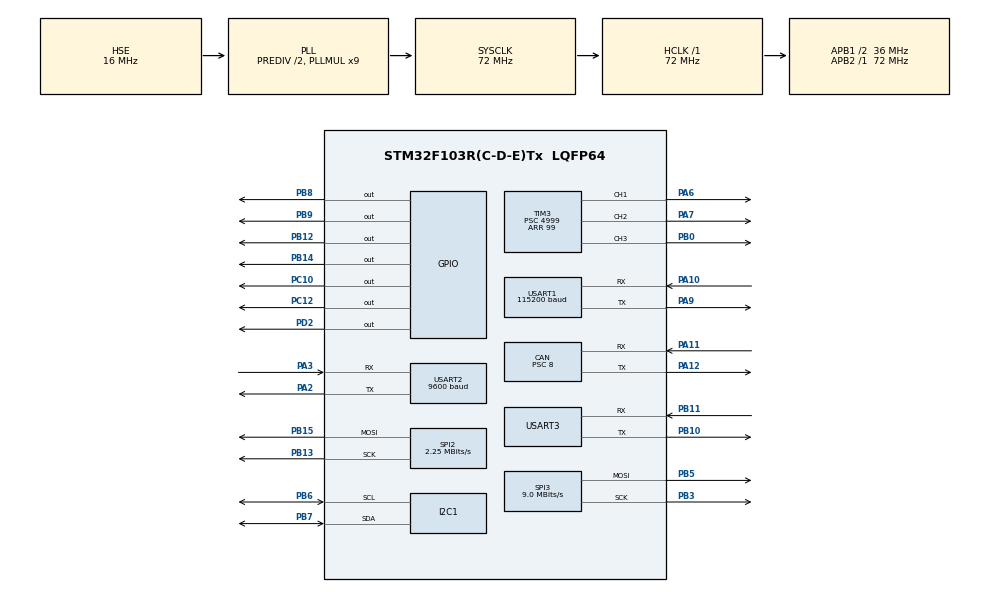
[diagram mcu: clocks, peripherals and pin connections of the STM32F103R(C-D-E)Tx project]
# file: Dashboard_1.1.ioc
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CAN.BS1=CAN_BS1_12TQ
CAN.BS2=CAN_BS2_5TQ
CAN.CalculateTimeBit=4000
CAN.CalculateTimeQuantum=222.22222222222223
CAN.Prescaler=8
I2C1.DutyCycle=I2C_DUTYCYCLE_2
I2C1.I2C_Mode=I2C_Fast
Mcu.Family=STM32F1
Mcu.Name=STM32F103R(C-D-E)Tx
Mcu.Package=LQFP64
NVIC.CAN1_RX1_IRQn=true\:0\:0\:false\:false\:true\:true\:true
NVIC.CAN1_SCE_IRQn=true\:0\:0\:false\:false\:true\:true\:true
NVIC.PriorityGroup=NVIC_PRIORITYGROUP_4
NVIC.USB_HP_CAN1_TX_IRQn=true\:0\:0\:false\:false\:true\:true\:true
NVIC.USB_LP_CAN1_RX0_IRQn=true\:0\:0\:false\:false\:true\:true\:true
PA10.Mode=Asynchronous
PA10.Signal=USART1_RX
PA11.GPIO_PuPd=GPIO_PULLUP
PA11.Mode=Master
PA11.Signal=CAN_RX
PA12.Mode=Master
PA12.Signal=CAN_TX
PA13.Mode=Serial_Wire
PA13.Signal=SYS_JTMS-SWDIO
PA14.Mode=Serial_Wire
PA14.Signal=SYS_JTCK-SWCLK
PA2.Mode=Asynchronous
PA2.Signal=USART2_TX
PA3.Mode=Asynchronous
PA3.Signal=USART2_RX
PA6.Signal=S_TIM3_CH1
PA7.Signal=S_TIM3_CH2
PA9.Mode=Asynchronous
PA9.Signal=USART1_TX
PB0.Signal=S_TIM3_CH3
PB10.Mode=Asynchronous
PB10.Signal=USART3_TX
PB11.Mode=Asynchronous
PB11.Signal=USART3_RX
PB12.GPIO_ModeDefaultOutputPP=GPIO_MODE_OUTPUT_PP
PB12.GPIO_PuPd=GPIO_NOPULL
PB12.GPIO_Speed=GPIO_SPEED_FREQ_LOW
PB12.PinState=GPIO_PIN_RESET
PB12.Signal=GPIO_Output
PB13.Mode=TX_Only_Simplex_Unidirect_Master
PB13.Signal=SPI2_SCK
PB14.GPIO_ModeDefaultOutputPP=GPIO_MODE_OUTPUT_PP
PB14.GPIO_PuPd=GPIO_NOPULL
PB14.GPIO_Speed=GPIO_SPEED_FREQ_LOW
PB14.PinState=GPIO_PIN_RESET
PB14.Signal=GPIO_Output
PB15.Mode=TX_Only_Simplex_Unidirect_Master
PB15.Signal=SPI2_MOSI
PB3.Mode=TX_Only_Simplex_Unidirect_Master
PB3.Signal=SPI3_SCK
PB5.Mode=TX_Only_Simplex_Unidirect_Master
PB5.Signal=SPI3_MOSI
PB6.Mode=I2C
PB6.Signal=I2C1_SCL
PB7.Mode=I2C
PB7.Signal=I2C1_SDA
PB8.GPIO_ModeDefaultOutputPP=GPIO_MODE_OUTPUT_PP
PB8.GPIO_PuPd=GPIO_NOPULL
PB8.GPIO_Speed=GPIO_SPEED_FREQ_LOW
PB8.PinState=GPIO_PIN_RESET
PB8.Signal=GPIO_Output
PB9.GPIO_ModeDefaultOutputPP=GPIO_MODE_OUTPUT_PP
PB9.GPIO_PuPd=GPIO_NOPULL
PB9.GPIO_Speed=GPIO_SPEED_FREQ_LOW
PB9.PinState=GPIO_PIN_RESET
PB9.Signal=GPIO_Output
PC10.GPIO_ModeDefaultOutputPP=GPIO_MODE_OUTPUT_PP
PC10.GPIO_PuPd=GPIO_NOPULL
PC10.GPIO_Speed=GPIO_SPEED_FREQ_LOW
PC10.PinState=GPIO_PIN_RESET
PC10.Signal=GPIO_Output
PC12.GPIO_ModeDefaultOutputPP=GPIO_MODE_OUTPUT_PP
PC12.GPIO_PuPd=GPIO_NOPULL
PC12.GPIO_Speed=GPIO_SPEED_FREQ_LOW
PC12.PinState=GPIO_PIN_RESET
PC12.Signal=GPIO_Output
PC14-OSC32_IN.Mode=LSE-External-Oscillator
PC14-OSC32_IN.Signal=RCC_OSC32_IN
PC15-OSC32_OUT.Mode=LSE-External-Oscillator
PC15-OSC32_OUT.Signal=RCC_OSC32_OUT
PD0-OSC_IN.Mode=HSE-External-Oscillator
PD0-OSC_IN.Signal=RCC_OSC_IN
PD1-OSC_OUT.Mode=HSE-External-Oscillator
PD1-OSC_OUT.Signal=RCC_OSC_OUT
PD2.GPIO_ModeDefaultOutputPP=GPIO_MODE_OUTPUT_PP
PD2.GPIO_PuPd=GPIO_NOPULL
PD2.GPIO_Speed=GPIO_SPEED_FREQ_LOW
PD2.PinState=GPIO_PIN_RESET
PD2.Signal=GPIO_Output
ProjectManager.HeapSize=0x200
ProjectManager.StackSize=0x400
ProjectManager.TargetToolchain=STM32CubeIDE
RCC.AHBFreq_Value=72000000
RCC.APB1CLKDivider=RCC_HCLK_DIV2
RCC.APB1Freq_Value=36000000
RCC.APB1TimFreq_Value=72000000
RCC.APB2Freq_Value=72000000
RCC.APB2TimFreq_Value=72000000
RCC.HCLKFreq_Value=72000000
RCC.HSEDivPLL=RCC_HSE_PREDIV_DIV2
RCC.HSE_VALUE=16000000
RCC.PLLMUL=RCC_PLL_MUL9
RCC.PLLSourceVirtual=RCC_PLLSOURCE_HSE
RCC.SYSCLKFreq_VALUE=72000000
RCC.SYSCLKSource=RCC_SYSCLKSOURCE_PLLCLK
RCC.USBFreq_Value=72000000
SH.S_TIM3_CH1.0=TIM3_CH1,PWM Generation1 CH1
SH.S_TIM3_CH2.0=TIM3_CH2,PWM Generation2 CH2
SH.S_TIM3_CH3.0=TIM3_CH3,PWM Generation3 CH3
SPI2.BaudRatePrescaler=SPI_BAUDRATEPRESCALER_16
SPI2.CalculateBaudRate=2.25 MBits/s
SPI2.Direction=SPI_DIRECTION_2LINES
SPI2.FirstBit=SPI_FIRSTBIT_LSB
SPI2.Mode=SPI_MODE_MASTER
SPI2.VirtualType=VM_MASTER
SPI3.BaudRatePrescaler=SPI_BAUDRATEPRESCALER_4
SPI3.CalculateBaudRate=9.0 MBits/s
SPI3.Direction=SPI_DIRECTION_2LINES
SPI3.Mode=SPI_MODE_MASTER
SPI3.VirtualType=VM_MASTER
TIM3.Channel-PWM\ Generation1\ CH1=TIM_CHANNEL_1
TIM3.Channel-PWM\ Generation2\ CH2=TIM_CHANNEL_2
TIM3.Channel-PWM\ Generation3\ CH3=TIM_CHANNEL_3
TIM3.Period=99
TIM3.Prescaler=4999
USART1.BaudRate=115200
USART1.VirtualMode=VM_ASYNC
USART2.BaudRate=9600
USART2.VirtualMode=VM_ASYNC
USART3.VirtualMode=VM_ASYNC
VP_TIM3_VS_ClockSourceINT.Mode=Internal
board=custom

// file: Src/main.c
/* USER CODE BEGIN Header */
/**
  ******************************************************************************
  * @file           : main.c
  * @brief          : Main program body
  ******************************************************************************
  * @attention
  *
  * <h2><center>&copy; Copyright (c) 2019 STMicroelectronics.
  * All rights reserved.</center></h2>
  *
  * This software component is licensed by ST under BSD 3-Clause license,
  * the "License"; You may not use this file except in compliance with the
  * License. You may obtain a copy of the License at:
  *                        opensource.org/licenses/BSD-3-Clause
  *
  ******************************************************************************
  */
/* USER CODE END Header */

#include "main.h"
#include "can.h"
#include "i2c.h"
#include "spi.h"
#include "tim.h"
#include "usart.h"
#include "gpio.h"

/* USER CODE BEGIN Includes */

#include "../GUI/gui.h"
#include "../GUI/gui.c"

#define SOFTWARE_VERSION "1.0"
#define SOFTWARE_RELASE_DATE "18.03.2019"

/* USER CODE END Includes */

/* USER CODE BEGIN PV */
/* Private variables ---------------------------------------------------------*/

/* USER CODE END PV */

void SystemClock_Config(void);
/* USER CODE BEGIN PFP */
/* Private function prototypes -----------------------------------------------*/

/* USER CODE END PFP */

int main(void)
{
  /* USER CODE BEGIN 1 */

// HAL_DBGMCU_EnableDBGSleepMode();
// HAL_DBGMCU_DisableDBGStopMode();
// HAL_DBGMCU_EnableDBGStandbyMode();

  /* USER CODE END 1 */

  /* MCU Configuration--------------------------------------------------------*/

  /* Reset of all peripherals, Initializes the Flash interface and the Systick. */
  HAL_Init();

  /* Configure the system clock */
  SystemClock_Config();

  /* Initialize all configured peripherals */
  MX_GPIO_Init();
  MX_CAN_Init();
  MX_I2C1_Init();
  MX_SPI2_Init();
  MX_SPI3_Init();
  MX_TIM3_Init();
  MX_USART1_UART_Init();
  MX_USART2_UART_Init();
  MX_USART3_UART_Init();
  /* USER CODE BEGIN 2 */

	gui_init();
	gui_screen_intro(); //test

//	gui_test();

  /* USER CODE END 2 */

  /* Infinite loop */
  while (1)
  {

    /* USER CODE BEGIN 3 */

	  gui_screen_main();

  }
  /* USER CODE END 3 */
}

void SystemClock_Config(void)
{
  RCC_OscInitTypeDef RCC_OscInitStruct = {0};
  RCC_ClkInitTypeDef RCC_ClkInitStruct = {0};

  /** Initializes the CPU, AHB and APB busses clocks
  */
  RCC_OscInitStruct.OscillatorType = RCC_OSCILLATORTYPE_HSE;
  RCC_OscInitStruct.HSEState = RCC_HSE_ON;
  RCC_OscInitStruct.HSEPredivValue = RCC_HSE_PREDIV_DIV2;
  RCC_OscInitStruct.HSIState = RCC_HSI_ON;
  RCC_OscInitStruct.PLL.PLLState = RCC_PLL_ON;
  RCC_OscInitStruct.PLL.PLLSource = RCC_PLLSOURCE_HSE;
  RCC_OscInitStruct.PLL.PLLMUL = RCC_PLL_MUL9;
  if (HAL_RCC_OscConfig(&RCC_OscInitStruct) != HAL_OK)
  {
    Error_Handler();
  }
  /** Initializes the CPU, AHB and APB busses clocks
  */
  RCC_ClkInitStruct.ClockType = RCC_CLOCKTYPE_HCLK|RCC_CLOCKTYPE_SYSCLK
                              |RCC_CLOCKTYPE_PCLK1|RCC_CLOCKTYPE_PCLK2;
  RCC_ClkInitStruct.SYSCLKSource = RCC_SYSCLKSOURCE_PLLCLK;
  RCC_ClkInitStruct.AHBCLKDivider = RCC_SYSCLK_DIV1;
  RCC_ClkInitStruct.APB1CLKDivider = RCC_HCLK_DIV2;
  RCC_ClkInitStruct.APB2CLKDivider = RCC_HCLK_DIV1;

  if (HAL_RCC_ClockConfig(&RCC_ClkInitStruct, FLASH_LATENCY_2) != HAL_OK)
  {
    Error_Handler();
  }
}

void Error_Handler(void)
{
  while(1)
  {
  }
}

/************************ (C) COPYRIGHT STMicroelectronics *****END OF FILE****/
